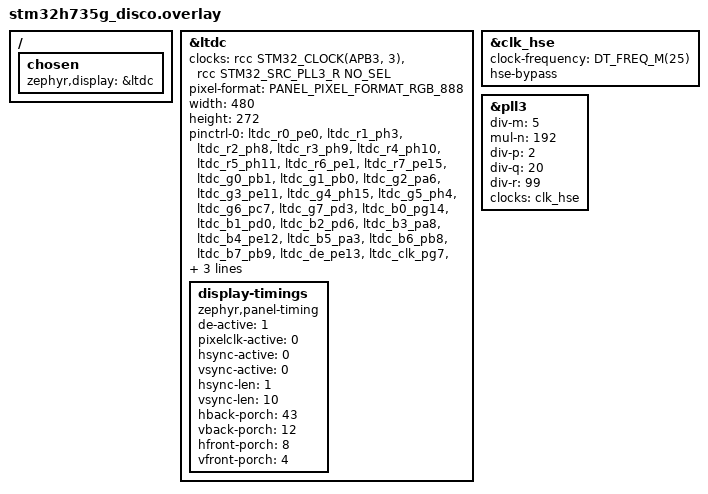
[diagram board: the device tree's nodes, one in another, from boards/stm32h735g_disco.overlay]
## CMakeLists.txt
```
cmake_minimum_required(VERSION 3.20.0)
find_package(Zephyr)
project(lvgl-threads)
target_sources(app PRIVATE src/main.c)

zephyr_code_relocate(FILES ${ZEPHYR_BASE}/modules/lvgl/lvgl_mem.c LOCATION DTCM)
zephyr_code_relocate(FILES ${ZEPHYR_BASE}/modules/lvgl/lvgl.c LOCATION DTCM)
```

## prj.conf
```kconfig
CONFIG_MAIN_STACK_SIZE=4096
CONFIG_CBPRINTF_FP_SUPPORT=y
CONFIG_DISPLAY=y
#CONFIG_DUMMY_DISPLAY=y

CONFIG_STM32_LTDC=y
CONFIG_STM32_LTDC_RGB565=y

CONFIG_LVGL=y
CONFIG_LV_USE_ST_LTDC=y
CONFIG_LV_Z_MEM_POOL_SIZE=65536
CONFIG_LV_Z_VDB_SIZE=10
CONFIG_LV_Z_BITS_PER_PIXEL=16
CONFIG_LV_Z_DOUBLE_VDB=y
CONFIG_LV_CONF_MINIMAL=y
CONFIG_LV_USE_THEME_DEFAULT=y
CONFIG_LV_FONT_MONTSERRAT_14=y
CONFIG_LV_FONT_MONTSERRAT_18=y
CONFIG_LV_USE_LABEL=y
CONFIG_LV_USE_SCALE=y
CONFIG_LV_USE_LINE=y
CONFIG_LV_USE_IMAGE=y
#CONFIG_LV_USE_LOG=y
#CONFIG_LV_LOG_PRINTF=y
#CONFIG_LV_LOG_LEVEL_ERROR=y
#CONFIG_LV_LOG_LEVEL_WARN=y
#CONFIG_LV_LOG_LEVEL_INFO=y

CONFIG_SHELL=y
CONFIG_LOG=y

#CONFIG_THREAD_ANALYZER=y
#CONFIG_THREAD_ANALYZER_AUTO=y
#CONFIG_THREAD_ANALYZER_AUTO_INTERVAL=5

CONFIG_CODE_DATA_RELOCATION=y
```

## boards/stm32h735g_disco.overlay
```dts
&ltdc {
    status = "okay";

    clocks = <&rcc STM32_CLOCK(APB3, 3)>,
		     <&rcc STM32_SRC_PLL3_R NO_SEL>;

    pixel-format = <PANEL_PIXEL_FORMAT_RGB_888>;
    width = <480>;
	height = <272>;

    pinctrl-0 = <
        &ltdc_r0_pe0  &ltdc_r1_ph3  &ltdc_r2_ph8    &ltdc_r3_ph9
        &ltdc_r4_ph10 &ltdc_r5_ph11 &ltdc_r6_pe1    &ltdc_r7_pe15
        &ltdc_g0_pb1  &ltdc_g1_pb0  &ltdc_g2_pa6    &ltdc_g3_pe11
        &ltdc_g4_ph15 &ltdc_g5_ph4  &ltdc_g6_pc7    &ltdc_g7_pd3
        &ltdc_b0_pg14 &ltdc_b1_pd0  &ltdc_b2_pd6    &ltdc_b3_pa8
        &ltdc_b4_pe12 &ltdc_b5_pa3  &ltdc_b6_pb8    &ltdc_b7_pb9
        &ltdc_de_pe13 &ltdc_clk_pg7 &ltdc_hsync_pc6 &ltdc_vsync_pa4
    >;

	pinctrl-names = "default";

	disp-on-gpios = <&gpiod 10 GPIO_ACTIVE_HIGH>;

    display-timings {
		compatible = "zephyr,panel-timing";
		de-active = <1>;
		pixelclk-active = <0>;
		hsync-active = <0>;
		vsync-active = <0>;
		hsync-len = <1>;
		vsync-len = <10>;
		hback-porch = <43>;
		vback-porch = <12>;
		hfront-porch = <8>;
		vfront-porch = <4>;
	};

    def-back-color-red = <0xFF>;
};

&clk_hse {
	clock-frequency = <DT_FREQ_M(25)>;
	hse-bypass;
	status = "okay";
};

&pll3 {
	div-m = <5>;
	mul-n = <192>;
	div-p = <2>;
	div-q = <20>;
	div-r = <99>;
	clocks = <&clk_hse>;
	status = "okay";
};

/ {
    chosen {
        zephyr,display = &ltdc;
    };
};
```

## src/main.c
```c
#include <zephyr/device.h>
#include <zephyr/devicetree.h>
#include <zephyr/drivers/display.h>
#include <zephyr/drivers/gpio.h>
#include <zephyr/kernel.h>
#include <lvgl.h>
#include <math.h>
#include <stdio.h>

#include "sensor.h"
#include "other_sensor.h"
#include "custom_scale.h"

volatile float sensor_value = 0.0f;
volatile float other_sensor_value = 0.0f;

int main(void)
{
    const struct device* display_dev = DEVICE_DT_GET(DT_CHOSEN(zephyr_display));

    if (!device_is_ready(display_dev))
        return -ENODEV;

    /* setup LVGL */
    // set background color
    lv_obj_set_style_bg_color(
        lv_screen_active(),
        lv_color_hex(0xFFFFFF),
        LV_PART_MAIN
    );

    // create grid layout
    static int32_t col_dsc[] = { LV_GRID_FR(1), LV_GRID_FR(1), LV_GRID_TEMPLATE_LAST };
    static int32_t row_dsc[] = { LV_GRID_FR(1), LV_GRID_TEMPLATE_LAST };

    lv_obj_set_layout(lv_screen_active(), LV_LAYOUT_GRID);
    lv_obj_set_grid_dsc_array(lv_screen_active(), col_dsc, row_dsc);

    // create 2 custom scales
    lv_obj_t *scale1, *line1, *label1,
             *scale2, *line2, *label2;

    setup_scale_custom(lv_screen_active(), &scale1, &line1, &label1);
    setup_scale_custom(lv_screen_active(), &scale2, &line2, &label2);

    lv_obj_set_grid_cell(
        scale1,
        LV_GRID_ALIGN_CENTER, 0, 1,
        LV_GRID_ALIGN_CENTER, 0, 1
    );

    lv_obj_set_grid_cell(
        scale2,
        LV_GRID_ALIGN_CENTER, 1, 1,
        LV_GRID_ALIGN_CENTER, 0, 1
    );

    /* LVGL main loop */
    display_blanking_off(display_dev);

    while (1)
    {
        // update scale
        update_scale_custom(scale1, line1, label1, sensor_value);
        update_scale_custom(scale2, line2, label2, other_sensor_value);

        // timers
        int sleep_ms = lv_timer_handler();
        k_msleep(sleep_ms);
    }

    return 0;
}

void update_sensor_val(void)
{
    while (1)
    {
        sensor_value = get_sensor_val();
        k_msleep(20);
    }
}

void update_other_sensor_val(void)
{
    while (1)
    {
        other_sensor_value = get_other_sensor_val();
        k_msleep(10);
    }
}

K_THREAD_DEFINE(
    other_sensor_thread,
    1024,
    update_other_sensor_val,
    NULL, NULL, NULL,
    7, 0, 0
);

K_THREAD_DEFINE(
    sensor_thread,
    1024,
    update_sensor_val,
    NULL, NULL, NULL,
    7, 0, 0
);
```

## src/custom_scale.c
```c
#include "custom_scale.h"

#include <stdio.h>
#include <math.h>

#define M_PI 3.14159265358979323846f
#define M_2PI (2.0f * M_PI)

void setup_scale_custom(lv_obj_t* parent, lv_obj_t** scale_ptr, lv_obj_t** line_ptr, lv_obj_t** label_ptr)
{
    // create scale
    lv_obj_t* scale = lv_scale_create(parent);

    lv_obj_set_size(scale, 150, 150);
    lv_scale_set_mode(scale, LV_SCALE_MODE_ROUND_INNER);

    lv_obj_set_style_text_font(
        scale,
        &lv_font_montserrat_14,
        LV_PART_MAIN
    ); 

    lv_obj_set_style_bg_opa(scale, LV_OPA_COVER, 0);
    lv_obj_set_style_bg_color(scale, lv_color_hex(0xDDDDDD), 0);
    lv_obj_set_style_radius(scale, LV_RADIUS_CIRCLE, 0);
    lv_obj_set_style_clip_corner(scale, true, 0);
    lv_obj_align(scale, LV_ALIGN_LEFT_MID, LV_PCT(2), 0);

    lv_scale_set_label_show(scale, true);

    lv_scale_set_total_tick_count(scale, 26);
    lv_scale_set_major_tick_every(scale, 5);

    lv_obj_set_style_length(scale, 5, LV_PART_ITEMS);
    lv_obj_set_style_length(scale, 10, LV_PART_INDICATOR);
    lv_scale_set_range(scale, 0, 25);

    lv_scale_set_angle_range(scale, 270);
    lv_scale_set_rotation(scale, 135);
    lv_obj_center(scale);

    // create scale line
    lv_obj_t* line = lv_line_create(scale);
    lv_obj_set_style_line_color(line, lv_color_hex(0xFF0000), LV_PART_MAIN);
    lv_obj_set_style_line_width(line, 6, LV_PART_MAIN);
    lv_obj_set_style_line_rounded(line, true, LV_PART_MAIN);

    // create label
    lv_obj_t* label = lv_label_create(scale);
    lv_label_set_text(label, ""); 

    lv_obj_set_style_text_font(
        label,
        &lv_font_montserrat_18,
        LV_PART_MAIN
    ); 
    
    lv_obj_set_style_text_color(
        lv_screen_active(),
        lv_color_hex(0x000000),
        LV_PART_MAIN
    );

    lv_obj_align(label, LV_ALIGN_BOTTOM_MID, 0, 0);

    // update pointers with addresses
    *scale_ptr = scale;
    *line_ptr = line;
    *label_ptr = label;
}

void update_scale_custom(lv_obj_t* scale, lv_obj_t* line, lv_obj_t* label, float val)
{
    // calculate scale and line parameters
    int LINE_LEN = 60;
    int LINE_OFFSET_X = lv_obj_get_width(scale) / 2;
    int LINE_OFFSET_Y = lv_obj_get_height(scale) / 2;

    int min = lv_scale_get_range_min_value(scale),
        max = lv_scale_get_range_max_value(scale),
        range = max - min,
        angle_range = lv_scale_get_angle_range(scale),
        rot = lv_scale_get_rotation(scale);

    // update label text
    char label_str[32];
    snprintf(label_str, sizeof(label_str), "%.1f", (double)val);

    lv_label_set_text(label, label_str);

    // get line_pts reference, or allocate it if necessary
    lv_point_precise_t* line_pts = lv_line_get_points_mutable(line);

    if (line_pts == NULL)
    {
        line_pts = lv_malloc(sizeof(lv_point_precise_t) * 2);
    }

    // update line_pts
    line_pts[0].x = LINE_OFFSET_X;
    line_pts[0].y = LINE_OFFSET_Y;

    float angle_mult =   M_2PI * (float)angle_range / 360.0f,
          angle_offset = M_2PI * (float)rot / 360.0f;
    line_pts[1].x = LINE_OFFSET_X + LINE_LEN * cosf(angle_mult * val / range + angle_offset);
    line_pts[1].y = LINE_OFFSET_Y + LINE_LEN * sinf(angle_mult * val / range + angle_offset);

    lv_line_set_points_mutable(line, line_pts, 2);
    lv_obj_move_foreground(line);
}
```

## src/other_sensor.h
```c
#pragma once
#include <zephyr/kernel.h>
#include <math.h>

float get_other_sensor_val(void)
{
    return fmodf((float)k_uptime_get() / 100.0f, 25.0f);
}
```

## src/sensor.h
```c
#pragma once
#include <zephyr/kernel.h>
#include <math.h>

float get_sensor_val(void)
{
    float uptime_s = (float)k_uptime_get() / 1000.0f;
    return 25.0f * (0.5f + 0.5f * sinf(uptime_s));
}
```
